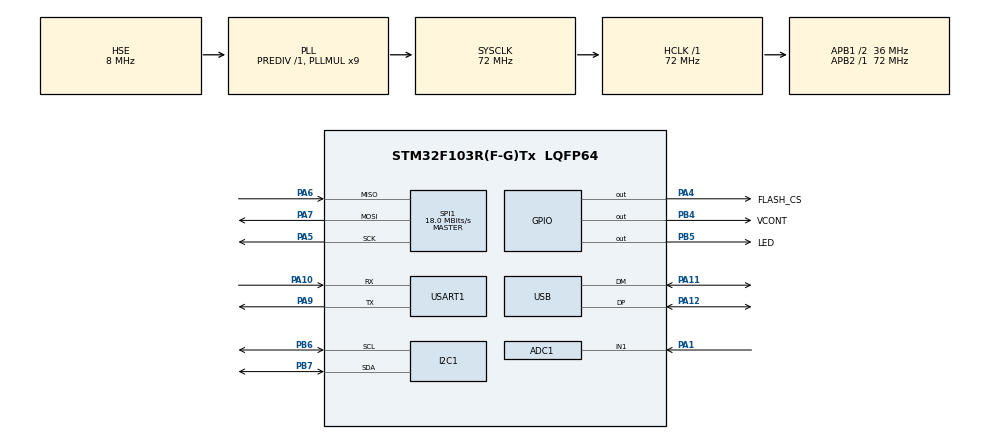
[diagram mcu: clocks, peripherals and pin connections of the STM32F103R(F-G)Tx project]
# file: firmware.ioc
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ADC1.Channel-0\#ChannelRegularConversion=ADC_CHANNEL_1
ADC1.NbrOfConversionFlag=1
ADC1.Rank-0\#ChannelRegularConversion=1
ADC1.SamplingTime-0\#ChannelRegularConversion=ADC_SAMPLETIME_41CYCLES_5
ADC1.master=1
FATFS._MAX_SS=4096
FATFS._MIN_SS=4096
Mcu.Family=STM32F1
Mcu.Name=STM32F103R(F-G)Tx
Mcu.Package=LQFP64
NVIC.PriorityGroup=NVIC_PRIORITYGROUP_4
NVIC.RTC_Alarm_IRQn=true\:0\:0\:false\:false\:true\:true\:true\:true
NVIC.USB_HP_CAN1_TX_IRQn=true\:0\:0\:true\:false\:true\:true\:true\:true
NVIC.USB_LP_CAN1_RX0_IRQn=true\:0\:0\:true\:false\:true\:true\:true\:true
PA0-WKUP.Mode=SYS_WakeUp0
PA0-WKUP.Signal=SYS_WKUP
PA1.Signal=ADCx_IN1
PA10.Mode=Asynchronous
PA10.Signal=USART1_RX
PA11.Mode=Device
PA11.Signal=USB_DM
PA12.Mode=Device
PA12.Signal=USB_DP
PA13.Mode=Serial_Wire
PA13.Signal=SYS_JTMS-SWDIO
PA14.Mode=Serial_Wire
PA14.Signal=SYS_JTCK-SWCLK
PA4.GPIO_Label=FLASH_CS
PA4.GPIO_PuPd=GPIO_PULLUP
PA4.GPIO_Speed=GPIO_SPEED_FREQ_HIGH
PA4.PinState=GPIO_PIN_SET
PA4.Signal=GPIO_Output
PA5.Mode=Full_Duplex_Master
PA5.Signal=SPI1_SCK
PA6.Mode=Full_Duplex_Master
PA6.Signal=SPI1_MISO
PA7.Mode=Full_Duplex_Master
PA7.Signal=SPI1_MOSI
PA9.Mode=Asynchronous
PA9.Signal=USART1_TX
PB4.GPIO_Label=VCONT
PB4.GPIO_PuPd=GPIO_PULLDOWN
PB4.Signal=GPIO_Output
PB5.GPIO_Label=LED
PB5.PinState=GPIO_PIN_SET
PB5.Signal=GPIO_Output
PB6.Mode=I2C
PB6.Signal=I2C1_SCL
PB7.Mode=I2C
PB7.Signal=I2C1_SDA
PC14-OSC32_IN.Mode=LSE-External-Oscillator
PC14-OSC32_IN.Signal=RCC_OSC32_IN
PC15-OSC32_OUT.Mode=LSE-External-Oscillator
PC15-OSC32_OUT.Signal=RCC_OSC32_OUT
PD0-OSC_IN.Mode=HSE-External-Oscillator
PD0-OSC_IN.Signal=RCC_OSC_IN
PD1-OSC_OUT.Mode=HSE-External-Oscillator
PD1-OSC_OUT.Signal=RCC_OSC_OUT
ProjectManager.HeapSize=0x2000
ProjectManager.StackSize=0x1000
ProjectManager.TargetToolchain=MDK-ARM V5.32
RCC.ADCPresc=RCC_ADCPCLK2_DIV6
RCC.AHBFreq_Value=72000000
RCC.APB1CLKDivider=RCC_HCLK_DIV2
RCC.APB1Freq_Value=36000000
RCC.APB1TimFreq_Value=72000000
RCC.APB2Freq_Value=72000000
RCC.APB2TimFreq_Value=72000000
RCC.HCLKFreq_Value=72000000
RCC.PLLMUL=RCC_PLL_MUL9
RCC.PLLSourceVirtual=RCC_PLLSOURCE_HSE
RCC.RTCClockSelection=RCC_RTCCLKSOURCE_LSE
RCC.SYSCLKFreq_VALUE=72000000
RCC.SYSCLKSource=RCC_SYSCLKSOURCE_PLLCLK
RCC.USBFreq_Value=48000000
RCC.USBPrescaler=RCC_USBCLKSOURCE_PLL_DIV1_5
SH.ADCx_IN1.0=ADC1_IN1,IN1
SPI1.BaudRatePrescaler=SPI_BAUDRATEPRESCALER_4
SPI1.CLKPhase=SPI_PHASE_2EDGE
SPI1.CLKPolarity=SPI_POLARITY_HIGH
SPI1.CalculateBaudRate=18.0 MBits/s
SPI1.Direction=SPI_DIRECTION_2LINES
SPI1.Mode=SPI_MODE_MASTER
SPI1.VirtualType=VM_MASTER
USART1.VirtualMode=VM_ASYNC
USB_DEVICE.CLASS_NAME_FS=MSC
USB_DEVICE.MSC_MEDIA_PACKET=4096
USB_DEVICE.USBD_MAX_STR_DESC_SIZ=2048
USB_DEVICE.VirtualMode=Msc
USB_DEVICE.VirtualModeFS=Msc_FS
VP_ADC1_Vref_Input.Mode=IN-Vrefint
VP_FATFS_VS_Generic.Mode=User_defined
VP_RTC_VS_RTC_Activate.Mode=RTC_Enabled
VP_USB_DEVICE_VS_USB_DEVICE_MSC_FS.Mode=MSC_FS
board=custom

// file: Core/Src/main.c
/* USER CODE BEGIN Header */
/**
  ******************************************************************************
  * @file           : main.c
  * @brief          : Main program body
  ******************************************************************************
  * @attention
  *
  * Copyright (c) 2023 STMicroelectronics.
  * All rights reserved.
  *
  * This software is licensed under terms that can be found in the LICENSE file
  * in the root directory of this software component.
  * If no LICENSE file comes with this software, it is provided AS-IS.
  *
  ******************************************************************************
  */
/* USER CODE END Header */
#include "main.h"
#include "adc.h"
#include "fatfs.h"
#include "i2c.h"
#include "rtc.h"
#include "spi.h"
#include "usart.h"
#include "usb_device.h"
#include "gpio.h"

/* USER CODE BEGIN Includes */
#include "run.h"
/* USER CODE END Includes */

void SystemClock_Config(void);

int main(void)
{

  /* MCU Configuration--------------------------------------------------------*/

  /* Reset of all peripherals, Initializes the Flash interface and the Systick. */
  HAL_Init();

  /* Configure the system clock */
  SystemClock_Config();

  /* USER CODE BEGIN SysInit */
  if (__HAL_PWR_GET_FLAG(PWR_FLAG_SB) != RESET)//检查并检查系统是否从待机模式恢复
  {
    /* Clear Standby flag */
    __HAL_PWR_CLEAR_FLAG(PWR_FLAG_SB);
  }
  /* USER CODE END SysInit */

  /* Initialize all configured peripherals */
  MX_GPIO_Init();
  MX_ADC1_Init();
  MX_I2C1_Init();
  MX_USART1_UART_Init();
  MX_FATFS_Init();
  MX_USB_DEVICE_Init();
  MX_RTC_Init();
  MX_SPI1_Init();
  /* USER CODE BEGIN 2 */
  //HAL_TIM_Base_Start_IT(&htim1);
  HAL_ADCEx_Calibration_Start(&hadc1);
  HAL_ADC_Start(&hadc1);
	setup();
  /* USER CODE END 2 */

  /* Infinite loop */
  while (1)
  {

    /* USER CODE BEGIN 3 */
	  loop();
  }
  /* USER CODE END 3 */
}

void SystemClock_Config(void)
{
  RCC_OscInitTypeDef RCC_OscInitStruct = {0};
  RCC_ClkInitTypeDef RCC_ClkInitStruct = {0};
  RCC_PeriphCLKInitTypeDef PeriphClkInit = {0};

  /** Initializes the RCC Oscillators according to the specified parameters
  * in the RCC_OscInitTypeDef structure.
  */
  RCC_OscInitStruct.OscillatorType = RCC_OSCILLATORTYPE_HSE|RCC_OSCILLATORTYPE_LSE;
  RCC_OscInitStruct.HSEState = RCC_HSE_ON;
  RCC_OscInitStruct.HSEPredivValue = RCC_HSE_PREDIV_DIV1;
  RCC_OscInitStruct.LSEState = RCC_LSE_ON;
  RCC_OscInitStruct.HSIState = RCC_HSI_ON;
  RCC_OscInitStruct.PLL.PLLState = RCC_PLL_ON;
  RCC_OscInitStruct.PLL.PLLSource = RCC_PLLSOURCE_HSE;
  RCC_OscInitStruct.PLL.PLLMUL = RCC_PLL_MUL9;
  if (HAL_RCC_OscConfig(&RCC_OscInitStruct) != HAL_OK)
  {
    Error_Handler();
  }

  /** Initializes the CPU, AHB and APB buses clocks
  */
  RCC_ClkInitStruct.ClockType = RCC_CLOCKTYPE_HCLK|RCC_CLOCKTYPE_SYSCLK
                              |RCC_CLOCKTYPE_PCLK1|RCC_CLOCKTYPE_PCLK2;
  RCC_ClkInitStruct.SYSCLKSource = RCC_SYSCLKSOURCE_PLLCLK;
  RCC_ClkInitStruct.AHBCLKDivider = RCC_SYSCLK_DIV1;
  RCC_ClkInitStruct.APB1CLKDivider = RCC_HCLK_DIV2;
  RCC_ClkInitStruct.APB2CLKDivider = RCC_HCLK_DIV1;

  if (HAL_RCC_ClockConfig(&RCC_ClkInitStruct, FLASH_LATENCY_2) != HAL_OK)
  {
    Error_Handler();
  }
  PeriphClkInit.PeriphClockSelection = RCC_PERIPHCLK_RTC|RCC_PERIPHCLK_ADC
                              |RCC_PERIPHCLK_USB;
  PeriphClkInit.RTCClockSelection = RCC_RTCCLKSOURCE_LSE;
  PeriphClkInit.AdcClockSelection = RCC_ADCPCLK2_DIV6;
  PeriphClkInit.UsbClockSelection = RCC_USBCLKSOURCE_PLL_DIV1_5;
  if (HAL_RCCEx_PeriphCLKConfig(&PeriphClkInit) != HAL_OK)
  {
    Error_Handler();
  }
}

void Error_Handler(void)
{
  __disable_irq();
  while (1)
  {
  }
}
